# STM32GBK1CBT6 register map
File version: 1.2
CPU: CM4 r0p1, little endian, MPU, FPU, 4 interrupt priority bits
Registers are 32-bit, read-write, reset 0x0 unless marked. A register's access mark holds for its fields unless they carry their own. Offsets are from the block's base; [hi:lo] are bit positions; {n}, {i} and the like mark numbered series.

## PWR — Power control
Base 0x40007000
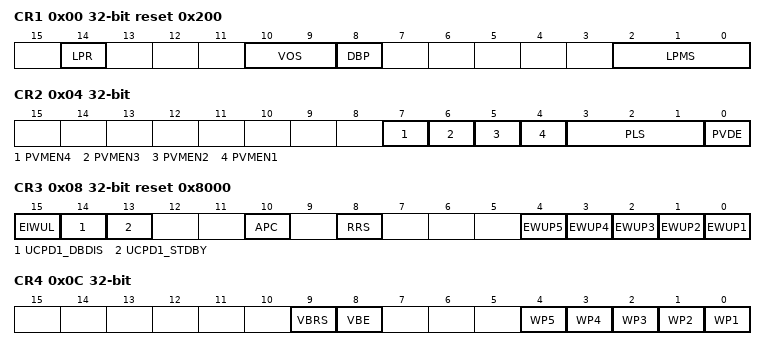
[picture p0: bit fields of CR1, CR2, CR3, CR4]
0x00 CR1 reset 0x200 — Power control register 1
  [14] LPR — Low-power run
  [10:9] VOS — Voltage scaling range selection
  [8] DBP — Disable backup domain write protection
  [2:0] LPMS — Low-power mode selection
0x04 CR2 — Power control register 2
  [7] PVMEN4 — Peripheral voltage monitoring 4 enable: VDDA vs. OPAMP/DAC min voltage
  [6] PVMEN3 — Peripheral voltage monitoring 3 enable: VDDA vs. ADC min voltage 1.62V
  [5] PVMEN2 — Peripheral voltage monitoring 2 enable: VDDA vs. Fast DAC min voltage
  [4] PVMEN1 — Peripheral voltage monitoring 1 enable: VDDA vs. COMP min voltage
  [3:1] PLS — Power voltage detector level selection
  [0] PVDE — Power voltage detector enable
0x08 CR3 reset 0x8000 — Power control register 3
  [15] EIWUL — Enable external WakeUp line
  [14] UCPD1_DBDIS — DBDIS
  [13] UCPD1_STDBY — STDBY
  [10] APC — Apply pull-up and pull-down configuration
  [8] RRS — SRAM2 retention in Standby mode
  [n-1] EWUP{n} (n=1..5) — Enable Wakeup pin WKUP{n}
0x0C CR4 — Power control register 4
  [9] VBRS — VBAT battery charging resistor selection
  [8] VBE — VBAT battery charging enable
  [n-1] WP{n} (n=1..5) — Wakeup pin WKUP{n} polarity
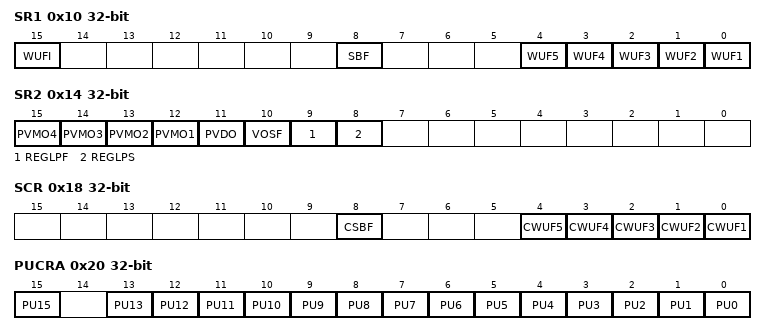
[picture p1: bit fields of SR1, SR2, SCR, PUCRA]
0x10 SR1 ro — Power status register 1
  [15] WUFI — Wakeup flag internal
  [8] SBF — Standby flag
  [n-1] WUF{n} (n=1..5) — Wakeup flag {n}
0x14 SR2 ro — Power status register 2
  [15] PVMO4 — Peripheral voltage monitoring output: VDDA vs. 2.2 V
  [14] PVMO3 — Peripheral voltage monitoring output: VDDA vs. 1.62 V
  [13] PVMO2 — Peripheral voltage monitoring output: VDDIO2 vs. 0.9 V
  [12] PVMO1 — Peripheral voltage monitoring output: VDDUSB vs. 1.2 V
  [11] PVDO — Power voltage detector output
  [10] VOSF — Voltage scaling flag
  [9] REGLPF — Low-power regulator flag
  [8] REGLPS — Low-power regulator started
0x18 SCR wo — Power status clear register
  [8] CSBF — Clear standby flag
  [n-1] CWUF{n} (n=1..5) — Clear wakeup flag {n}
0x20 PUCRA — Power Port A pull-up control register
  [15] PU15 — Port A pull-up bit y (y=0..15)
  [n] PU{n} (n=0..13) — Port A pull-up bit y (y=0..15)
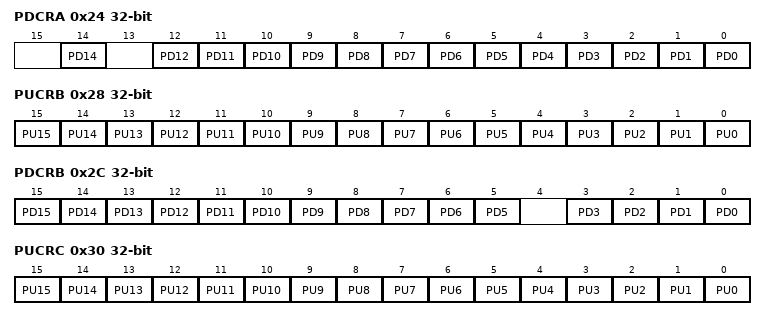
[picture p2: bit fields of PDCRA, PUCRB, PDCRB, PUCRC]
0x24 PDCRA — Power Port A pull-down control register
  [14] PD14 — Port A pull-down bit y (y=0..15)
  [n] PD{n} (n=0..12) — Port A pull-down bit y (y=0..15)
0x28 PUCRB — Power Port B pull-up control register
  [n] PU{n} (n=0..15) — Port B pull-up bit y (y=0..15)
0x2C PDCRB — Power Port B pull-down control register
  [n] PD{n} (n=5..15) — Port B pull-down bit y (y=0..15)
  [n] PD{n} (n=0..3) — Port B pull-down bit y (y=0..15)
0x30 PUCRC — Power Port C pull-up control register
  [n] PU{n} (n=0..15) — Port C pull-up bit y (y=0..15)
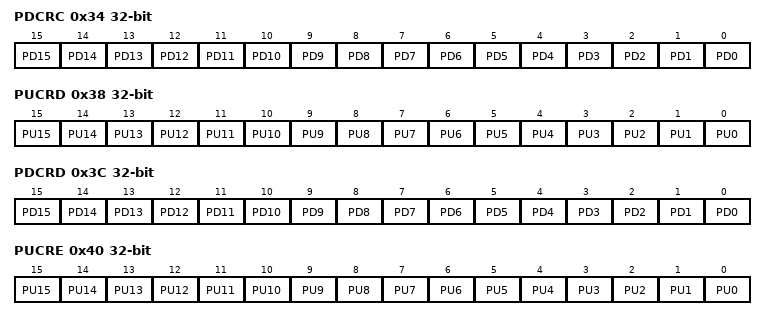
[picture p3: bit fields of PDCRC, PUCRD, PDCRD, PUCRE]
0x34 PDCRC — Power Port C pull-down control register
  [n] PD{n} (n=0..15) — Port C pull-down bit y (y=0..15)
0x38 PUCRD — Power Port D pull-up control register
  [n] PU{n} (n=0..15) — Port D pull-up bit y (y=0..15)
0x3C PDCRD — Power Port D pull-down control register
  [n] PD{n} (n=0..15) — Port D pull-down bit y (y=0..15)
0x40 PUCRE — Power Port E pull-up control register
  [n] PU{n} (n=0..15) — Port E pull-up bit y (y=0..15)
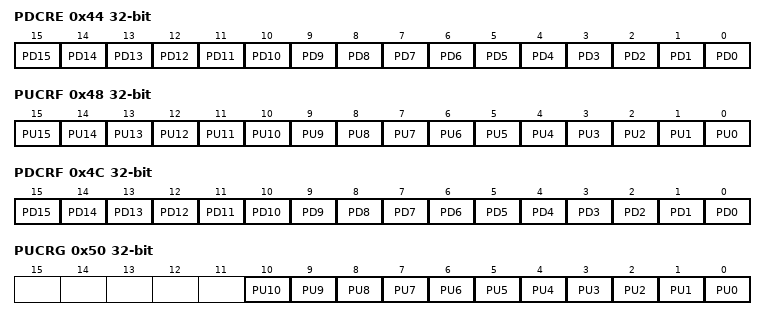
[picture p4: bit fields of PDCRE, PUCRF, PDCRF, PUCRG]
0x44 PDCRE — Power Port E pull-down control register
  [n] PD{n} (n=0..15) — Port E pull-down bit y (y=0..15)
0x48 PUCRF — Power Port F pull-up control register
  [n] PU{n} (n=0..15) — Port F pull-up bit y (y=0..15)
0x4C PDCRF — Power Port F pull-down control register
  [n] PD{n} (n=0..15) — Port F pull-down bit y (y=0..15)
0x50 PUCRG — Power Port G pull-up control register
  [n] PU{n} (n=0..10) — Port G pull-up bit y (y=0..15)
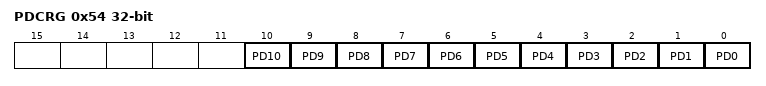
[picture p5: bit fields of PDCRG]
0x54 PDCRG — Power Port G pull-down control register
  [n] PD{n} (n=0..10) — Port G pull-down bit y (y=0..15)
0x80 CR5 reset 0x100 — Power control register 5
  [0] R1MODE — Main regular range 1 mode
